CM_ "AUTOGENERATED FILE, DO NOT EDIT"

CM_ "Imported file _comma.dbc starts here"
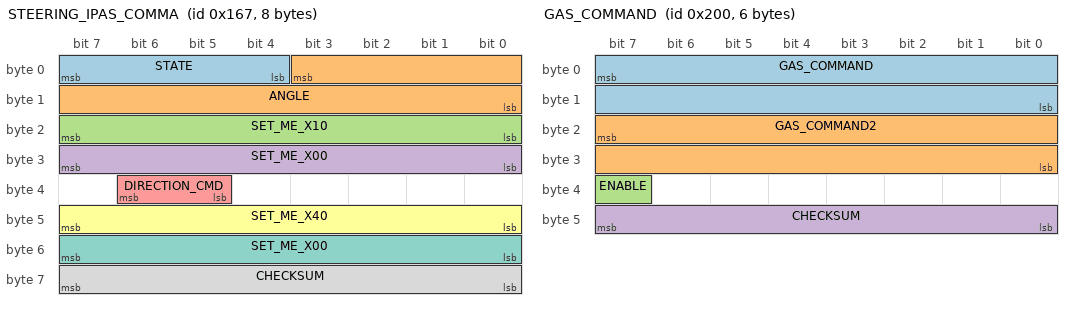
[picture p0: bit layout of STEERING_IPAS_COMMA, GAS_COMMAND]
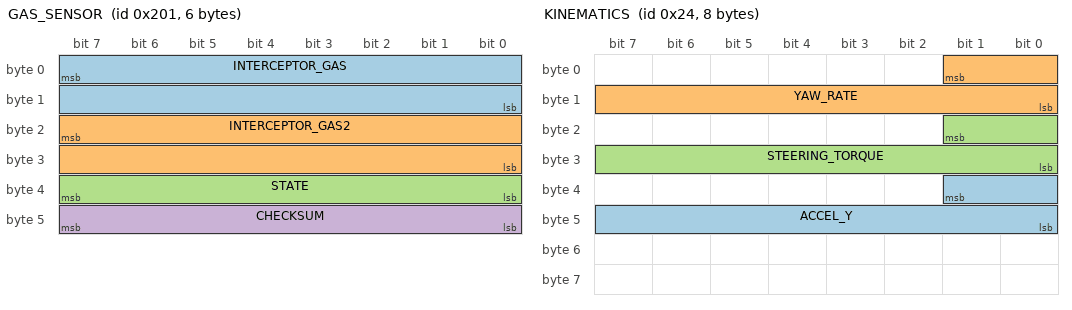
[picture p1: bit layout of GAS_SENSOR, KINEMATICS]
BO_ 359 STEERING_IPAS_COMMA: 8 IPAS
 SG_ STATE : 7|4@0+ (1,0) [0|15] "" XXX
 SG_ ANGLE : 3|12@0- (1.5,0) [-510|510] "deg" XXX
 SG_ SET_ME_X10 : 23|8@0+ (1,0) [0|255] "" XXX
 SG_ SET_ME_X00 : 31|8@0+ (1,0) [0|255] "" XXX
 SG_ DIRECTION_CMD : 38|2@0+ (1,0) [0|3] "" XXX
 SG_ SET_ME_X40 : 47|8@0+ (1,0) [0|255] "" XXX
 SG_ SET_ME_X00 : 55|8@0+ (1,0) [0|255] "" XXX
 SG_ CHECKSUM : 63|8@0+ (1,0) [0|255] "" XXX

CM BO_ STEERING_IPAS_COMMA "Copy of msg 614 so we can do angle control while the Park Assist ECU is connected (Panda spoofs 614 with 359 on connector J70). Note that addresses 0x266 and 0x167 are checksum-invariant";

 BO_ 512 GAS_COMMAND: 6 EON
  SG_ GAS_COMMAND : 7|16@0+ (0.159375,-75.555) [0|1] "" INTERCEPTOR
  SG_ GAS_COMMAND2 : 23|16@0+ (0.159375,-151.111) [0|1] "" INTERCEPTOR
  SG_ ENABLE : 39|1@0+ (1,0) [0|1] "" INTERCEPTOR
  SG_ CHECKSUM : 47|8@0+ (1,0) [0|3] "" INTERCEPTOR

 BO_ 513 GAS_SENSOR: 6 INTERCEPTOR
  SG_ INTERCEPTOR_GAS : 7|16@0+ (0.159375,-75.555) [0|1] "" EON
  SG_ INTERCEPTOR_GAS2 : 23|16@0+ (0.159375,-151.111) [0|1] "" EON
  SG_ STATE : 39|8@0+ (1,0) [0|255] "" EON
  SG_ CHECKSUM : 47|8@0+ (1,0) [0|3] "" EON

 VAL_ 513 STATE 5 "FAULT_TIMEOUT" 4 "FAULT_STARTUP" 3 "FAULT_SCE" 2 "FAULT_SEND" 1 "FAULT_BAD_CHECKSUM" 0 "NO_FAULT" ;

CM_ "Imported file _toyota_2017.dbc starts here"
VERSION ""

NS_ :

BS_:

BU_: XXX DSU HCU EPS IPAS

BO_ 36 KINEMATICS: 8 XXX
 SG_ ACCEL_Y : 33|10@0+ (1,-512) [0|65535] "" XXX
 SG_ YAW_RATE : 1|10@0+ (1,-512) [0|65535] "" XXX
 SG_ STEERING_TORQUE : 17|10@0+ (1,-512) [0|65535] "" XXX

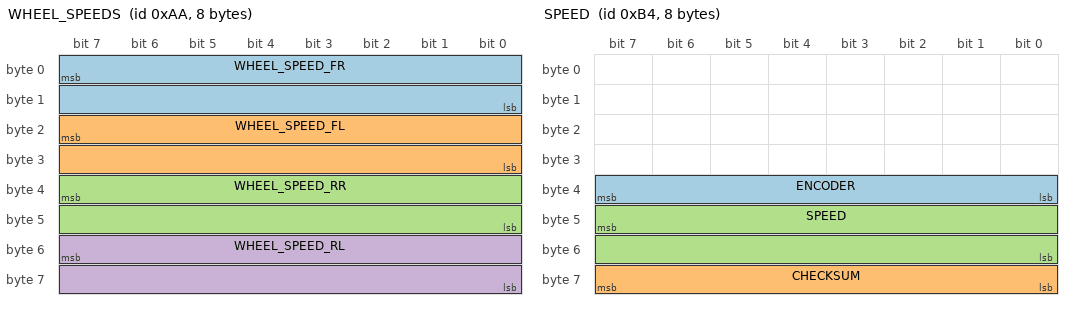
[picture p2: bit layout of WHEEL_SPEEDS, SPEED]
BO_ 170 WHEEL_SPEEDS: 8 XXX
 SG_ WHEEL_SPEED_FR : 7|16@0+ (0.01,-67.67) [0|250] "kph" XXX
 SG_ WHEEL_SPEED_FL : 23|16@0+ (0.01,-67.67) [0|250] "kph" XXX
 SG_ WHEEL_SPEED_RR : 39|16@0+ (0.01,-67.67) [0|250] "kph" XXX
 SG_ WHEEL_SPEED_RL : 55|16@0+ (0.01,-67.67) [0|250] "kph" XXX

BO_ 180 SPEED: 8 XXX
 SG_ ENCODER : 39|8@0+ (1,0) [0|255] "" XXX
 SG_ CHECKSUM : 63|8@0+ (1,0) [0|255] "" XXX
 SG_ SPEED : 47|16@0+ (0.01,0) [0|250] "kph" XXX

BO_ 353 DSU_SPEED: 8 XXX
 SG_ FORWARD_SPEED : 15|16@0- (0.00390625,-30) [0|255] "kph" XXX

BO_ 466 PCM_CRUISE: 8 XXX
 SG_ GAS_RELEASED : 4|1@0+ (1,0) [0|1] "" XXX
 SG_ CRUISE_STATE : 5|1@0+ (1,0) [0|1] "" XXX
 SG_ CRUISE_ACTIVE : 5|1@0+ (1,0) [0|1] "" XXX

BO_ 552 ACCELEROMETER: 8 XXX
 SG_ ACCEL_Z : 22|15@0- (1,0) [0|32767] "" XXX
 SG_ ACCEL_X : 6|15@0- (0.001,0) [-20|20] "m/s2" XXX

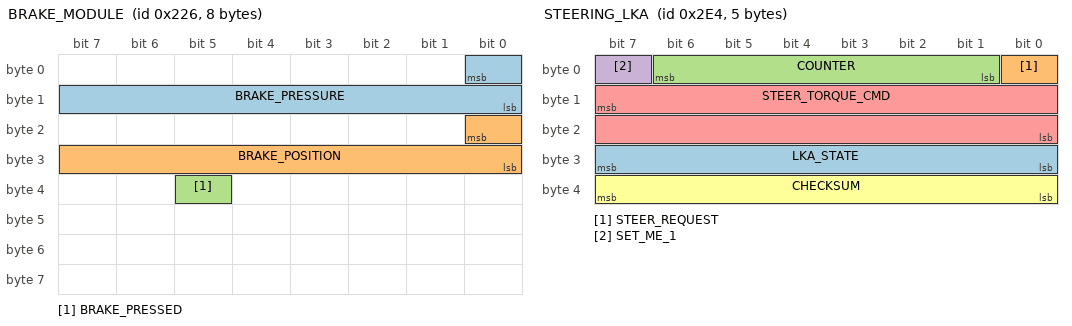
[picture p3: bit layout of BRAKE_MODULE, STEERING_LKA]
BO_ 550 BRAKE_MODULE: 8 XXX
 SG_ BRAKE_PRESSURE : 0|9@0+ (1,0) [0|511] "" XXX
 SG_ BRAKE_POSITION : 16|9@0+ (1,0) [0|511] "" XXX
 SG_ BRAKE_PRESSED : 37|1@0+ (1,0) [0|1] "" XXX

BO_ 740 STEERING_LKA: 5 XXX
 SG_ LKA_STATE : 31|8@0+ (1,0) [0|255] "" XXX
 SG_ STEER_REQUEST : 0|1@0+ (1,0) [0|1] "" XXX
 SG_ COUNTER : 6|6@0+ (1,0) [0|63] "" XXX
 SG_ SET_ME_1 : 7|1@0+ (1,0) [0|1] "" XXX
 SG_ STEER_TORQUE_CMD : 15|16@0- (1,0) [0|65535] "" XXX
 SG_ CHECKSUM : 39|8@0+ (1,0) [0|255] "" XXX

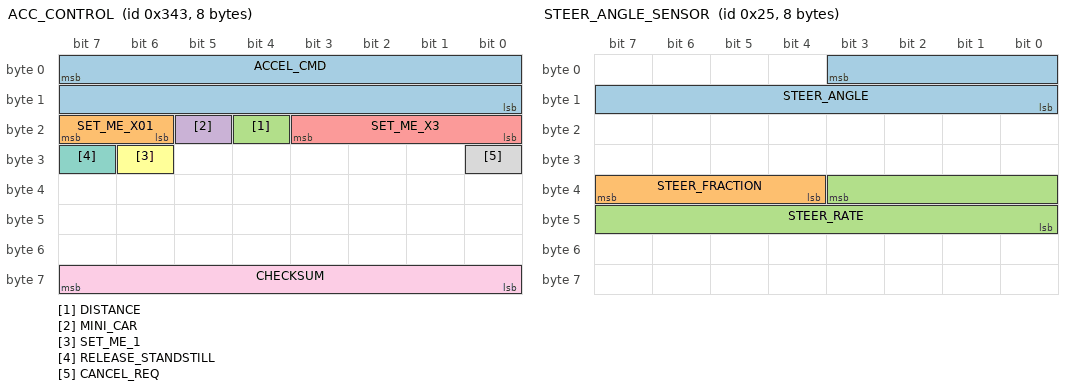
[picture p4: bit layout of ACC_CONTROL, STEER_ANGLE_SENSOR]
BO_ 835 ACC_CONTROL: 8 DSU
 SG_ ACCEL_CMD : 7|16@0- (0.001,0) [-20|20] "m/s2" HCU
 SG_ SET_ME_X01 : 23|2@0+ (1,0) [0|3] "" HCU
 SG_ DISTANCE : 20|1@0+ (1,0) [0|1] "" XXX
 SG_ MINI_CAR : 21|1@0+ (1,0) [0|1] "" XXX
 SG_ SET_ME_X3 : 19|4@0+ (1,0) [0|15] "" XXX
 SG_ SET_ME_1 : 30|1@0+ (1,0) [0|1] "" HCU
 SG_ RELEASE_STANDSTILL : 31|1@0+ (1,0) [0|1] "" HCU
 SG_ CANCEL_REQ : 24|1@0+ (1,0) [0|1] "" HCU
 SG_ CHECKSUM : 63|8@0+ (1,0) [0|255] "" XXX

BO_ 1556 STEERING_LEVERS: 8 XXX
 SG_ TURN_SIGNALS : 29|2@0+ (1,0) [0|3] "" XXX

BO_ 37 STEER_ANGLE_SENSOR: 8 XXX
 SG_ STEER_ANGLE : 3|12@0- (1.5,0) [-500|500] "deg" XXX
 SG_ STEER_FRACTION : 39|4@0- (0.1,0) [-0.7|0.7] "deg" XXX
 SG_ STEER_RATE : 35|12@0- (1,0) [-2000|2000] "deg/s" XXX

BO_ 951 ESP_CONTROL: 8 ESP
 SG_ TC_DISABLED : 13|1@0+ (1,0) [0|1] "" XXX
 SG_ BRAKE_LIGHTS_ACC : 18|1@0+ (1,0) [0|1] "" XXX

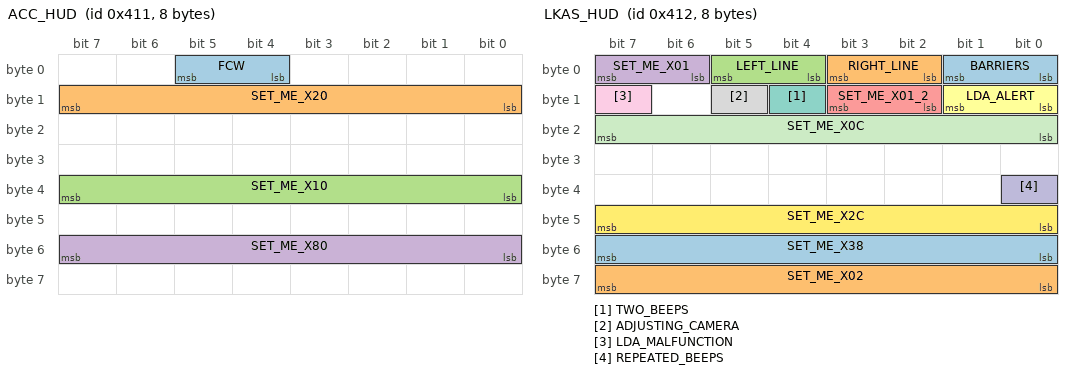
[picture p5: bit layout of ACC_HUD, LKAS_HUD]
BO_ 1041 ACC_HUD: 8 DSU
 SG_ FCW : 5|2@0+ (1,0) [0|0] "" FCM
 SG_ SET_ME_X20 : 15|8@0+ (1,0) [0|1] "" XXX
 SG_ SET_ME_X10 : 39|8@0+ (1,0) [0|1] "" XXX
 SG_ SET_ME_X80 : 55|8@0+ (1,0) [0|1] "" XXX

BO_ 1042 LKAS_HUD: 8 XXX
 SG_ BARRIERS : 1|2@0+ (1,0) [0|3] "" XXX
 SG_ RIGHT_LINE : 3|2@0+ (1,0) [0|3] "" XXX
 SG_ LEFT_LINE : 5|2@0+ (1,0) [0|3] "" XXX
 SG_ SET_ME_X01 : 7|2@0+ (1,0) [0|3] "" XXX
 SG_ SET_ME_X01_2 : 11|2@0+ (1,0) [0|3] "" XXX
 SG_ LDA_ALERT : 9|2@0+ (1,0) [0|3] "" XXX
 SG_ TWO_BEEPS : 12|1@0+ (1,0) [0|1] "" XXX
 SG_ ADJUSTING_CAMERA : 13|1@0+ (1,0) [0|1] "" XXX
 SG_ LDA_MALFUNCTION : 15|1@0+ (1,0) [0|1] "" XXX
 SG_ REPEATED_BEEPS : 32|1@0+ (1,0) [0|1] "" XXX
 SG_ SET_ME_X0C : 23|8@0+ (1,0) [0|1] "" XXX
 SG_ SET_ME_X2C : 47|8@0+ (1,0) [0|1] "" XXX
 SG_ SET_ME_X38 : 55|8@0+ (1,0) [0|1] "" XXX
 SG_ SET_ME_X02 : 63|8@0+ (1,0) [0|1] "" XXX

BO_ 1553 UI_SEETING: 8 XXX
 SG_ UNITS : 26|2@0+ (1,0) [0|3] "" XXX

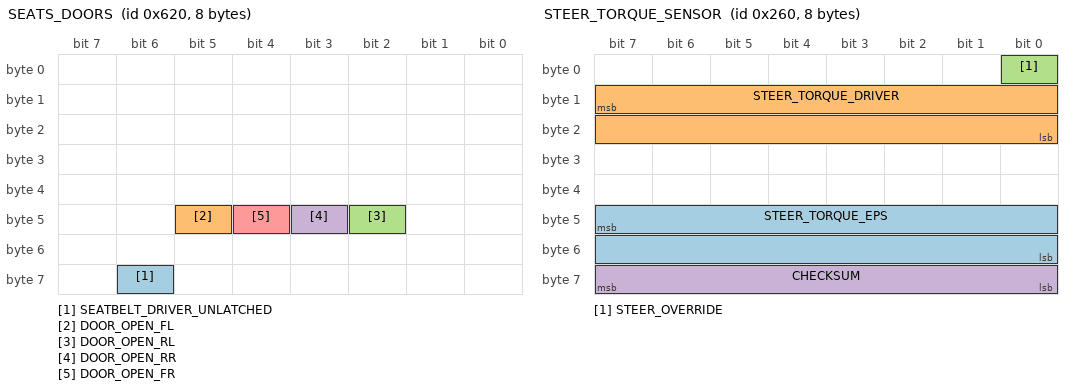
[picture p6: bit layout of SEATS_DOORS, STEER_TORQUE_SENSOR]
BO_ 1568 SEATS_DOORS: 8 XXX
 SG_ SEATBELT_DRIVER_UNLATCHED : 62|1@0+ (1,0) [0|1] "" XXX
 SG_ DOOR_OPEN_FL : 45|1@0+ (1,0) [0|1] "" XXX
 SG_ DOOR_OPEN_RL : 42|1@0+ (1,0) [0|1] "" XXX
 SG_ DOOR_OPEN_RR : 43|1@0+ (1,0) [0|1] "" XXX
 SG_ DOOR_OPEN_FR : 44|1@0+ (1,0) [0|1] "" XXX

BO_ 1599 LIGHT_STALK: 8 SCM
 SG_ AUTO_HIGH_BEAM : 19|1@0+ (1,0) [0|1] "" XXX

CM_ SG_ 36 ACCEL_Y "unit is tbd";
CM_ SG_ 36 YAW_RATE "verify";
CM_ SG_ 36 STEERING_TORQUE "does not seem the steer torque, tbd";
CM_ SG_ 466 ACCEL_NET "net acceleration produced by the system, given ACCEL_CMD, road grade and other factors";
CM_ SG_ 560 BRAKE_PRESSED "another brake pressed?";
CM_ SG_ 951 BRAKE_LIGHTS_ACC "brake lights when ACC commands decel";
CM_ SG_ 608 STEER_TORQUE_DRIVER "driver torque";
CM_ SG_ 608 STEER_OVERRIDE "set when driver torque exceeds a certain value";
CM_ SG_ 37 STEER_FRACTION "1/15th of the signal STEER_ANGLE, which is 1.5 deg; note that 0x8 is never set";
CM_ SG_ 37 STEER_RATE "factor is tbd";
CM_ SG_ 1042 SET_ME_1 "unclear what this is, but it's always 1 in drive traces";
CM_ SG_ 1042 REPEATED_BEEPS "recommended for fcw and other important alerts";
VAL_ 466 CRUISE_STATE 8 "active" 7 "standstill" 1 "off" ;
VAL_ 1553 UNITS 1 "km" 2 "miles";
VAL_ 1556 TURN_SIGNALS 3 "none" 2 "right" 1 "left" ;
VAL_ 1042 LDA_ALERT 3 "hold with continuous beep" 2 "LDA unavailable" 1 "hold" 0 "none";
VAL_ 1042 BARRIERS 3 "both" 2 "right" 1 "left" 0 "none";
VAL_ 1042 RIGHT_LINE 3 "orange" 2 "double" 1 "solid" 0 "none";
VAL_ 1042 LEFT_LINE 3 "orange" 2 "double" 1 "solid" 0 "none";

CM_ "CHFFR_METRIC 37 STEER_ANGLE STEER_ANGLE 0.36 180";

CM_ "lexus_is_hybrid_2017_pt.dbc starts here"

BO_ 581 GAS_PEDAL: 5 XXX
 SG_ GAS_PEDAL : 23|8@0+ (0.005,0) [0|1] "" XXX

BO_ 608 STEER_TORQUE_SENSOR: 8 XXX
 SG_ STEER_TORQUE_EPS : 47|16@0- (0.66,0) [-20000|20000] "" XXX
 SG_ STEER_TORQUE_DRIVER : 15|16@0- (1,0) [-32768|32767] "" XXX
 SG_ STEER_OVERRIDE : 0|1@0+ (1,0) [0|1] "" XXX
 SG_ CHECKSUM : 63|8@0+ (1,0) [0|255] "" XXX

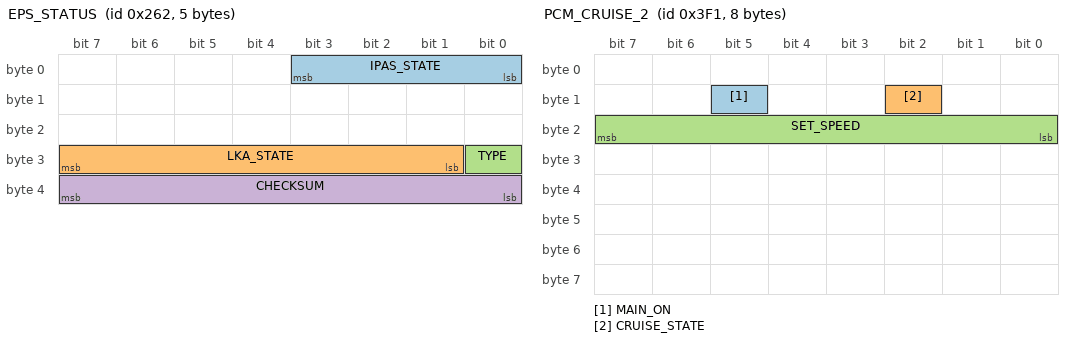
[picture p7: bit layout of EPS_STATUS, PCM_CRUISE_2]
BO_ 610 EPS_STATUS: 5 EPS
 SG_ IPAS_STATE : 3|4@0+ (1,0) [0|15] "" XXX
 SG_ LKA_STATE : 31|7@0+ (1,0) [0|127] "" XXX
 SG_ TYPE : 24|1@0+ (1,0) [0|1] "" XXX
 SG_ CHECKSUM : 39|8@0+ (1,0) [0|255] "" XXX

BO_ 956 GEAR_PACKET: 8 XXX
 SG_ GEAR : 13|6@0+ (1,0) [0|63] "" XXX

BO_ 1009 PCM_CRUISE_2: 8 XXX
 SG_ MAIN_ON : 13|1@0+ (1,0) [0|3] "" XXX
 SG_ CRUISE_STATE : 10|1@0+ (1,0) [0|1] "" XXX
 SG_ SET_SPEED : 23|8@0+ (1,0) [0|255] "kph" XXX

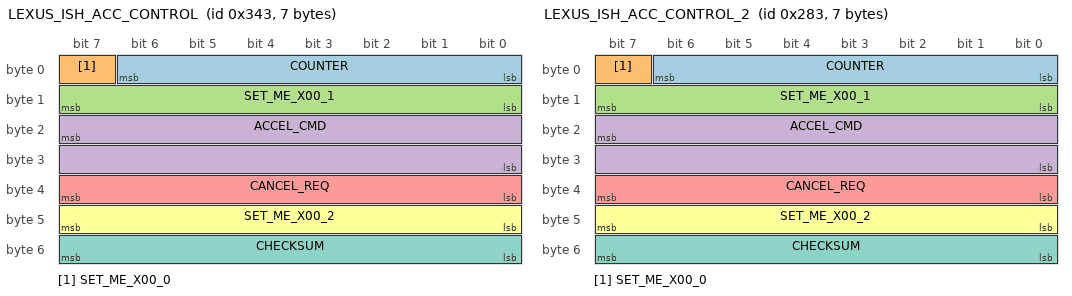
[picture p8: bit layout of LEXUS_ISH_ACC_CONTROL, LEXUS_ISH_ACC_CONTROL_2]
BO_ 835 LEXUS_ISH_ACC_CONTROL: 7 DS1
 SG_ COUNTER : 6|7@0+ (1,0) [0|127] "" XXX
 SG_ SET_ME_X00_0 : 7|1@0+ (1,0) [0|1] "" Vector__XXX
 SG_ SET_ME_X00_1 : 15|8@0+ (1,0) [0|255] "" XXX
 SG_ ACCEL_CMD : 23|16@0- (0.001,0) [-20|20] "m/s2" Vector__XXX
 SG_ CANCEL_REQ : 39|8@0+ (1,0) [0|255] "" XXX
 SG_ SET_ME_X00_2 : 47|8@0+ (1,0) [0|255] "" XXX
 SG_ CHECKSUM : 55|8@0+ (1,0) [0|0] "" FCM

BO_ 643 LEXUS_ISH_ACC_CONTROL_2: 7 DS1
 SG_ COUNTER : 6|7@0+ (1,0) [0|127] "" XXX
 SG_ SET_ME_X00_0 : 7|1@0+ (1,0) [0|1] "" Vector__XXX
 SG_ SET_ME_X00_1 : 15|8@0+ (1,0) [0|255] "" XXX
 SG_ ACCEL_CMD : 23|16@0- (0.001,0) [-20|20] "m/s2" Vector__XXX
 SG_ CANCEL_REQ : 39|8@0+ (1,0) [0|255] "" XXX
 SG_ SET_ME_X00_2 : 47|8@0+ (1,0) [0|255] "" XXX
 SG_ CHECKSUM : 55|8@0+ (1,0) [0|0] "" FCM

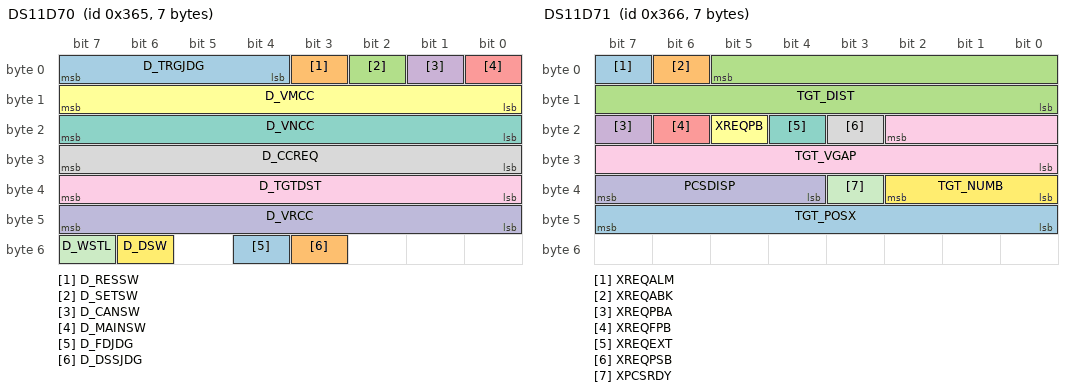
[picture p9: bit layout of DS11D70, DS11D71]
BO_ 869 DS11D70: 7 DS1
 SG_ D_TRGJDG : 7|4@0+ (1,0) [0|0] "" Vector__XXX
 SG_ D_RESSW : 3|1@0+ (1,0) [0|0] "" Vector__XXX
 SG_ D_SETSW : 2|1@0+ (1,0) [0|0] "" Vector__XXX
 SG_ D_CANSW : 1|1@0+ (1,0) [0|0] "" Vector__XXX
 SG_ D_MAINSW : 0|1@0+ (1,0) [0|0] "" Vector__XXX
 SG_ D_VMCC : 15|8@0+ (1,0) [0|0] "km/h" Vector__XXX
 SG_ D_VNCC : 23|8@0+ (1,0) [0|0] "km/h" Vector__XXX
 SG_ D_CCREQ : 31|8@0+ (100,-12800) [0|0] "N" Vector__XXX
 SG_ D_TGTDST : 39|8@0+ (1,0) [0|0] "m" Vector__XXX
 SG_ D_VRCC : 47|8@0- (1,0) [0|0] "km/h" Vector__XXX
 SG_ D_WSTL : 55|1@0+ (1,0) [0|0] "" Vector__XXX
 SG_ D_DSW : 54|1@0+ (1,0) [0|0] "" Vector__XXX
 SG_ D_FDJDG : 52|1@0+ (1,0) [0|0] "" Vector__XXX
 SG_ D_DSSJDG : 51|1@0+ (1,0) [0|0] "" Vector__XXX

BO_ 870 DS11D71: 7 DS1
 SG_ XREQALM : 7|1@0+ (1,0) [0|0] "" Vector__XXX
 SG_ XREQABK : 6|1@0+ (1,0) [0|0] "" Vector__XXX
 SG_ TGT_DIST : 5|14@0+ (0.01,0) [0|0] "m" Vector__XXX
 SG_ XREQPBA : 23|1@0+ (1,0) [0|0] "" Vector__XXX
 SG_ XREQFPB : 22|1@0+ (1,0) [0|0] "" Vector__XXX
 SG_ XREQPB : 21|1@0+ (1,0) [0|0] "" Vector__XXX
 SG_ XREQEXT : 20|1@0+ (1,0) [0|0] "" Vector__XXX
 SG_ XREQPSB : 19|1@0+ (1,0) [0|0] "" Vector__XXX
 SG_ TGT_VGAP : 18|11@0+ (0.025,-51.175) [0|0] "m/s" Vector__XXX
 SG_ PCSDISP : 39|4@0+ (1,0) [0|0] "" Vector__XXX
 SG_ XPCSRDY : 35|1@0+ (1,0) [0|0] "" Vector__XXX
 SG_ TGT_NUMB : 34|3@0+ (1,1) [0|0] "" Vector__XXX
 SG_ TGT_POSX : 47|8@0- (0.04,0) [0|0] "m" Vector__XXX

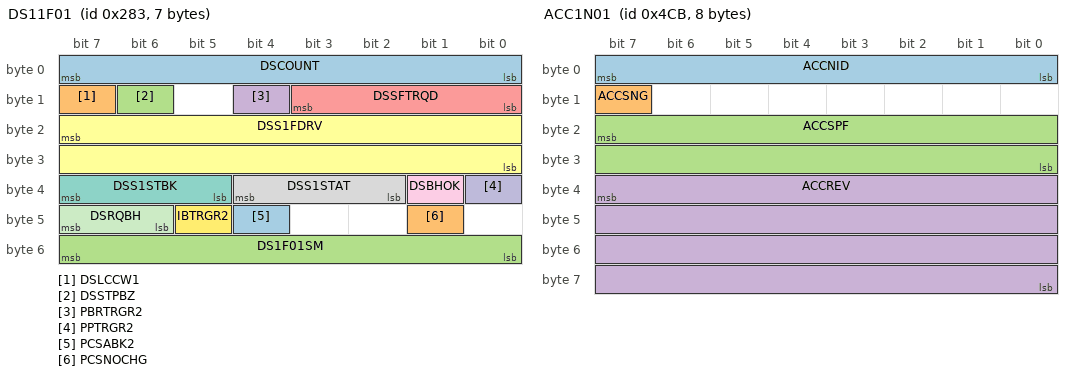
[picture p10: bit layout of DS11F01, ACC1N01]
BO_ 643 DS11F01: 7 DS1
 SG_ DSCOUNT : 7|8@0+ (1,0) [0|0] "" Vector__XXX
 SG_ DSLCCW1 : 15|1@0+ (1,0) [0|0] "" FCM
 SG_ DSSTPBZ : 14|1@0+ (1,0) [0|0] "" FCM
 SG_ PBRTRGR2 : 12|1@0+ (1,0) [0|0] "" Vector__XXX
 SG_ DSSFTRQD : 11|4@0+ (1,0) [0|0] "" Vector__XXX
 SG_ DSS1FDRV : 23|16@0- (2,0) [0|0] "N" Vector__XXX
 SG_ DSS1STBK : 39|3@0+ (1,0) [0|0] "" Vector__XXX
 SG_ DSS1STAT : 36|3@0+ (1,0) [0|0] "" Vector__XXX
 SG_ DSBHOK : 33|1@0+ (1,0) [0|0] "" Vector__XXX
 SG_ PPTRGR2 : 32|1@0+ (1,0) [0|0] "" Vector__XXX
 SG_ DSRQBH : 47|2@0+ (1,0) [0|0] "" Vector__XXX
 SG_ IBTRGR2 : 45|1@0+ (1,0) [0|0] "" Vector__XXX
 SG_ PCSABK2 : 44|1@0+ (1,0) [0|0] "" Vector__XXX
 SG_ PCSNOCHG : 41|1@0+ (1,0) [0|0] "" Vector__XXX
 SG_ DS1F01SM : 55|8@0+ (1,0) [0|0] "" FCM

BO_ 836 ACC1F01: 8 DS1
 SG_ DSS1GDRV : 7|10@0- (0.1,0) [0|0] "m/s^2" Vector__XXX
 SG_ DS1STAT2 : 13|3@0+ (1,0) [0|0] "" Vector__XXX
 SG_ DS1STBK2 : 10|3@0+ (1,0) [0|0] "" Vector__XXX
 SG_ PCSWAR : 18|1@0+ (1,0) [0|0] "" FCM
 SG_ PCSALM : 17|1@0+ (1,0) [0|0] "" FCM
 SG_ PCSOPR : 16|1@0+ (1,0) [0|0] "" Vector__XXX
 SG_ PCSABK : 31|1@0+ (1,0) [0|0] "" Vector__XXX
 SG_ PBATRGR : 30|2@0+ (1,0) [0|0] "" Vector__XXX
 SG_ PPTRGR : 28|1@0+ (1,0) [0|0] "" FCM
 SG_ IBTRGR : 27|1@0+ (1,0) [0|0] "" FCM
 SG_ CLEXTRGR : 26|1@0+ (1,0) [0|0] "" Vector__XXX
 SG_ IRLT_REQ : 25|2@0+ (1,0) [0|0] "" Vector__XXX
 SG_ BRKHLD : 37|1@0+ (1,0) [0|0] "" Vector__XXX
 SG_ AVSTRGR : 36|1@0+ (1,0) [0|0] "" SCS
 SG_ VGRSTRGR : 35|2@0+ (1,0) [0|0] "" Vector__XXX
 SG_ PREFILL : 33|1@0+ (1,0) [0|0] "" Vector__XXX
 SG_ PBRTRGR : 32|1@0+ (1,0) [0|0] "" Vector__XXX
 SG_ PCSDIS : 43|1@0+ (1,0) [0|0] "" Vector__XXX
 SG_ PBPREPMP : 40|1@0+ (1,0) [0|0] "" Vector__XXX
 SG_ ACCF01SM : 63|8@0+ (1,0) [0|0] "" FCM

BO_ 1227 ACC1N01: 8 DS1
 SG_ ACCNID : 7|8@0+ (1,0) [0|0] "" CGW
 SG_ ACCSNG : 15|1@0+ (1,0) [0|0] "" CGW
 SG_ ACCSPF : 23|16@0+ (1,0) [0|0] "" CGW
 SG_ ACCREV : 39|32@0+ (1,0) [0|0] "" CGW

CM_ SG_ 581 GAS_PEDAL "it seems slightly filtered";
CM_ SG_ 610 TYPE "seems 1 on Corolla, 0 on all others";
VAL_ 610 IPAS_STATE 5 "override" 3 "enabled" 1 "disabled";
VAL_ 610 LKA_STATE 25 "temporary_fault" 9 "temporary_fault2" 5 "active" 1 "standby";
VAL_ 956 GEAR 0 "D" 1 "S" 8 "N" 16 "R" 32 "P";
CM_ SG_ 869 D_MAINSW "ACC Switch";
CM_ SG_ 869 D_CANSW "ACC Cancel toggle";
CM_ SG_ 869 D_SETSW "ACC SET/- toggle";
CM_ SG_ 869 D_RESSW "ACC RES/+ toggle";
